# ATmega328PB register map
Vendor: Atmel; File version: 1.0
CPU: other r0p0, little endian, no MPU, no FPU, 4 interrupt priority bits
Registers are 8-bit, read-write, reset 0x0 unless marked. A register's access mark holds for its fields unless they carry their own. Offsets are from the block's base; [hi:lo] are bit positions; {n}, {i} and the like mark numbered series.

## ADC — Analog-to-Digital Converter
Base 0x00000078
0x00 ADC 16-bit (reset mask 0xFF) — ADC Data Register Bytes
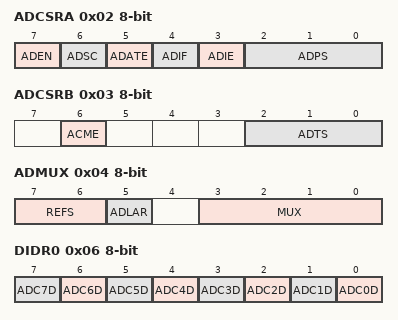
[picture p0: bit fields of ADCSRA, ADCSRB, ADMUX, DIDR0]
0x02 ADCSRA — The ADC Control and Status register A
  [7] ADEN — ADC Enable
  [6] ADSC — ADC Start Conversion
  [5] ADATE — ADC Auto Trigger Enable
  [4] ADIF — ADC Interrupt Flag
  [3] ADIE — ADC Interrupt Enable
  [2:0] ADPS — ADC Prescaler Select Bits
    1=2; 2=4; 3=8; 4=16; 5=32; 6=64; 7=128
0x03 ADCSRB — The ADC Control and Status register B
  [6] ACME — Analog Comparator Multiplexer Enable
  [2:0] ADTS — ADC Auto Trigger Source bits
    0=FREE_RUNNING_MODE; 1=ANALOG_COMPARATOR; 2=EXTERNAL_INTERRUPT_REQUEST_0; 3=TIMER_COUNTER0_COMPARE_MATCH_A; 4=TIMER_COUNTER0_OVERFLOW; 5=TIMER_COUNTER1_COMPARE_MATCH_B; 6=TIMER_COUNTER1_OVERFLOW; 7=TIMER_COUNTER1_CAPTURE_EVENT
0x04 ADMUX — The ADC multiplexer Selection Register
  [7:6] REFS — Reference Selection Bits
    0=AREF_INTERNAL_VREF_TURNED_OFF; 1=AVCC_WITH_EXTERNAL_CAPACITOR_AT_AREF_PIN; 3=INTERNAL_1_1V_VOLTAGE_REFERENCE_WITH_EXTERNAL_CAPACITOR_AT_AREF_PIN
  [5] ADLAR — Left Adjust Result
  [3:0] MUX — Analog Channel Selection Bits
    {v}=ADC{v} (ADC Single Ended Input pin {v}) (v=0..7); 8=TEMPSENS (Temperature sensor); 14=ADC_VBG (Internal Reference (VBG)); 15=ADC_GND (0V (GND))
0x06 DIDR0 — Digital Input Disable Register
  [n] ADC{n}D (n=0..7) — ADC Digital Input Disable

## CFD
Base 0x00000062
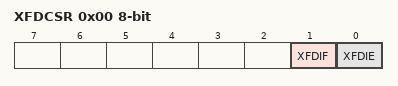
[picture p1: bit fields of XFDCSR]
0x00 XFDCSR — XOSC Failure Detection Control and Status Register
  [1] XFDIF — Failure Detection Interrupt Flag
  [0] XFDIE — Failure Detection Interrupt Enable

## CPU
Base 0x0000003E
0x00 GPIOR0 — General Purpose I/O Register 0
0x0C GPIOR1 — General Purpose I/O Register 1
0x0D GPIOR2 — General Purpose I/O Register 2
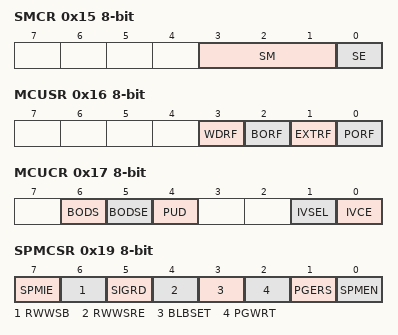
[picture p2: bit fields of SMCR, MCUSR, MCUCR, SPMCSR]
0x15 SMCR — Sleep Mode Control Register
  [3:1] SM — Sleep Mode Select Bits
    0=IDLE; 1=ADC (ADC Noise Reduction (If Available)); 2=PDOWN (Power Down); 3=PSAVE (Power Save); 6=STDBY (Standby); 7=ESTDBY (Extended Standby)
  [0] SE — Sleep Enable
0x16 MCUSR — MCU Status Register
  [3] WDRF — Watchdog Reset Flag
  [2] BORF — Brown-out Reset Flag
  [1] EXTRF — External Reset Flag
  [0] PORF — Power-on reset flag
0x17 MCUCR — MCU Control Register
  [6] BODS — BOD Sleep
  [5] BODSE — BOD Sleep Enable
  [4] PUD
  [1] IVSEL
  [0] IVCE
0x19 SPMCSR — Store Program Memory Control and Status Register
  [7] SPMIE — SPM Interrupt Enable
  [6] RWWSB — Read-While-Write Section Busy
  [5] SIGRD — Signature Row Read
  [4] RWWSRE — Read-While-Write section read enable
  [3] BLBSET — Boot Lock Bit Set
  [2] PGWRT — Page Write
  [1] PGERS — Page Erase
  [0] SPMEN — Store Program Memory
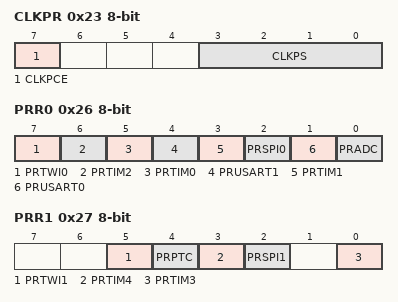
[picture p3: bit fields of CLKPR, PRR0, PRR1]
0x23 CLKPR — Clock Prescale Register
  [7] CLKPCE — Clock Prescaler Change Enable
  [3:0] CLKPS — Clock Prescaler Select Bits
    0=1; 1=2; 2=4; 3=8; 4=16; 5=32; 6=64; 7=128; 8=256
0x26 PRR0 — Power Reduction Register 0
  [7] PRTWI0 — Power Reduction TWI0
  [6] PRTIM2 — Power Reduction Timer/Counter2
  [5] PRTIM0 — Power Reduction Timer/Counter0
  [4] PRUSART1 — Power Reduction USART1
  [3] PRTIM1 — Power Reduction Timer/Counter1
  [2] PRSPI0 — Power Reduction Serial Peripheral Interface 1
  [1] PRUSART0 — Power Reduction USART0
  [0] PRADC — Power Reduction ADC
0x27 PRR1 — Power Reduction Register 1
  [5] PRTWI1 — Power Reduction TWI1
  [4] PRPTC — Power Reduction Peripheral Touch Controller
  [3] PRTIM4 — Power Reduction Timer/Counter4
  [2] PRSPI1 — Power Reduction Serial Peripheral Interface 1
  [0] PRTIM3 — Power Reduction Timer/Counter3
0x28 OSCCAL — Oscillator Calibration Value
  [7:0] OSCCAL — Oscillator Calibration

## EEPROM
Base 0x0000003F
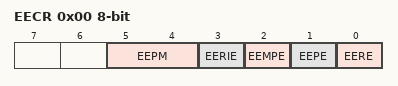
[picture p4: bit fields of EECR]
0x00 EECR — EEPROM Control Register
  [5:4] EEPM — EEPROM Programming Mode Bits
    0=ERASE_AND_WRITE_IN_ONE_OPERATION; 1=ERASE_ONLY; 2=WRITE_ONLY
  [3] EERIE — EEPROM Ready Interrupt Enable
  [2] EEMPE — EEPROM Master Write Enable
  [1] EEPE — EEPROM Write Enable
  [0] EERE — EEPROM Read Enable
0x01 EEDR — EEPROM Data Register
0x02 EEAR 16-bit (reset mask 0xFF) — EEPROM Address Register Bytes
